# STM32L552 register map
File version: 1.5
CPU: CM33 r0p1, little endian, MPU, FPU, 3 interrupt priority bits
Registers are 32-bit, read-write, reset 0x0 unless marked. A register's access mark holds for its fields unless they carry their own. Offsets are from the block's base; [hi:lo] are bit positions; {n}, {i} and the like mark numbered series; 'fields as' and 'values as' point back to an identical list.

## TAMP — Tamper and backup registers
Base 0x40003400
Same registers: SEC_TAMP 0x50003400
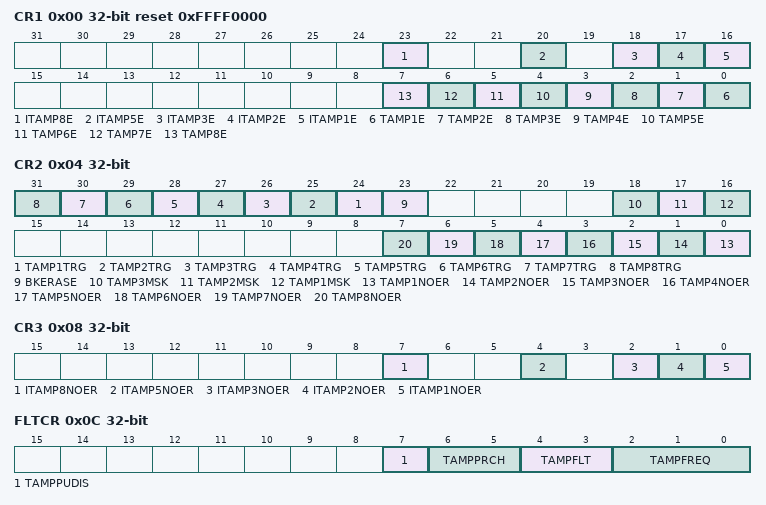
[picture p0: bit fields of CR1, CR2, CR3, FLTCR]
0x00 CR1 reset 0xFFFF0000 — control register 1
  [23] ITAMP8E — ITAMP5E
  [20] ITAMP5E
  [18] ITAMP3E
  [17] ITAMP2E
  [16] ITAMP1E
  [n-1] TAMP{n}E (n=1..8)
0x04 CR2 — control register 2
  [n+23] TAMP{n}TRG (n=1..8), [23] BKERASE, [18] TAMP3MSK, [17] TAMP2MSK, [16] TAMP1MSK, [n-1] TAMP{n}NOER (n=1..8)
0x08 CR3 — control register 3
  [7] ITAMP8NOER, [4] ITAMP5NOER, [2] ITAMP3NOER, [1] ITAMP2NOER, [0] ITAMP1NOER
0x0C FLTCR — TAMP filter control register
  [7] TAMPPUDIS, [6:5] TAMPPRCH, [4:3] TAMPFLT, [2:0] TAMPFREQ
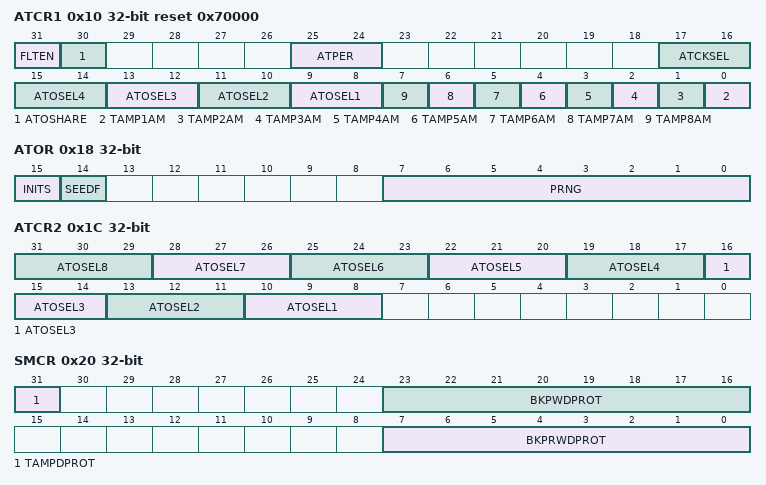
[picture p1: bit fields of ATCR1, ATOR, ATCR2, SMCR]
0x10 ATCR1 reset 0x70000 — TAMP active tamper control register 1
  [31] FLTEN, [30] ATOSHARE, [25:24] ATPER, [17:16] ATCKSEL, [2n+7:2n+6] ATOSEL{n} (n=1..4), [n-1] TAMP{n}AM (n=1..8)
0x14 ATSEEDR wo — TAMP active tamper seed register
  [31:0] SEED — Pseudo-random generator seed value
0x18 ATOR ro — TAMP active tamper output register
  [15] INITS — Active tamper initialization status
  [14] SEEDF — Seed running flag
  [7:0] PRNG — Pseudo-random generator value
0x1C ATCR2 — TAMP active tamper control register 2
  [3n+7:3n+5] ATOSEL{n} (n=1..8)
0x20 SMCR — TAMP secure mode register
  [31] TAMPDPROT — Tamper protection
  [23:16] BKPWDPROT — Backup registers write protection offset
  [7:0] BKPRWDPROT — Backup registers read/write protection offset
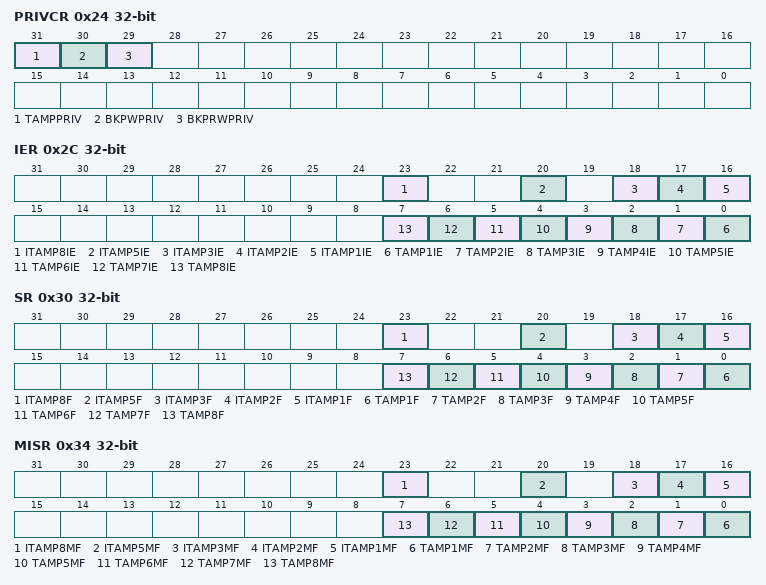
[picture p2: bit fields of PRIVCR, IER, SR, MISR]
0x24 PRIVCR — TAMP privilege mode control register
  [31] TAMPPRIV — Tamper privilege protection
  [30] BKPWPRIV — Backup registers zone 2 privilege protection
  [29] BKPRWPRIV — Backup registers zone 1 privilege protection
0x2C IER — TAMP interrupt enable register
  [23] ITAMP8IE, [20] ITAMP5IE, [18] ITAMP3IE, [17] ITAMP2IE, [16] ITAMP1IE, [n-1] TAMP{n}IE (n=1..8)
0x30 SR ro — TAMP status register
  [23] ITAMP8F, [20] ITAMP5F, [18] ITAMP3F, [17] ITAMP2F, [16] ITAMP1F, [n-1] TAMP{n}F (n=1..8)
0x34 MISR ro — TAMP masked interrupt status register
  [23] ITAMP8MF, [20] ITAMP5MF, [18] ITAMP3MF, [17] ITAMP2MF, [16] ITAMP1MF, [n-1] TAMP{n}MF (n=1..8)
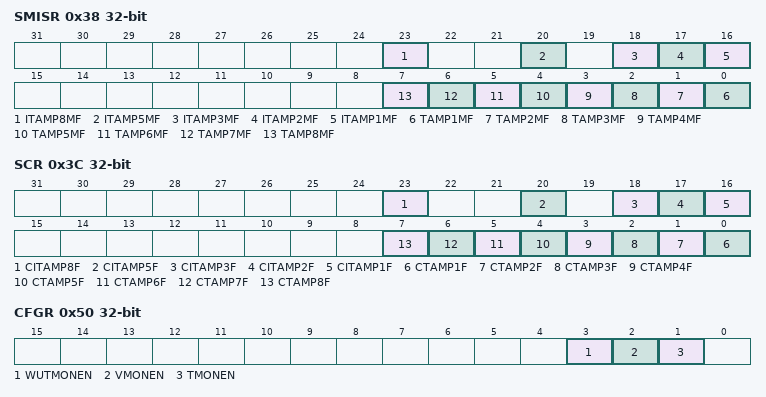
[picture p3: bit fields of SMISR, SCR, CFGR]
0x38 SMISR ro — TAMP secure masked interrupt status register
  fields as MISR
0x3C SCR wo — TAMP status clear register
  [23] CITAMP8F, [20] CITAMP5F, [18] CITAMP3F, [17] CITAMP2F, [16] CITAMP1F, [n-1] CTAMP{n}F (n=1..8)
0x40 COUNTR ro — TAMP monotonic counter register
  [31:0] COUNT
0x50 CFGR — TAMP configuration register
  [3] WUTMONEN, [2] VMONEN, [1] TMONEN
{0x100+4i} BKP{i}R (i=0..31) — TAMP backup register
  [31:0] BKP

## ICACHE
Base 0x40030400
Same registers: SEC_ICache 0x50030400
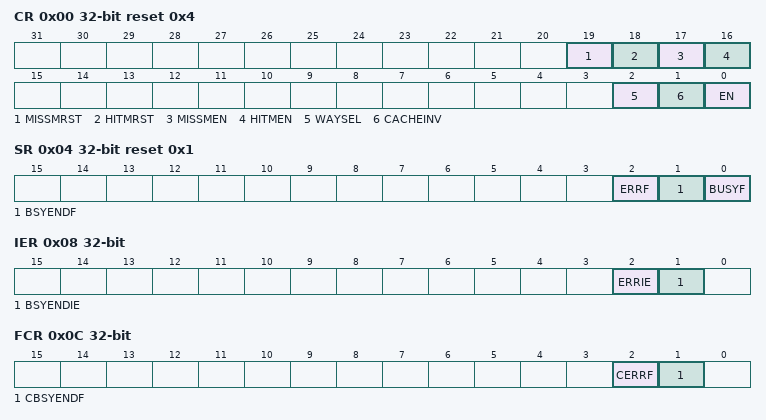
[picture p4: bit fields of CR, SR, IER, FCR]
0x00 CR reset 0x4 — ICACHE control register
  [19] MISSMRST, [18] HITMRST, [17] MISSMEN, [16] HITMEN, [2] WAYSEL, [1] CACHEINV, [0] EN
0x04 SR ro reset 0x1 — ICACHE status register
  [2] ERRF, [1] BSYENDF, [0] BUSYF
0x08 IER — ICACHE interrupt enable register
  [2] ERRIE, [1] BSYENDIE
0x0C FCR wo — ICACHE flag clear register
  [2] CERRF, [1] CBSYENDF
0x10 HMONR ro — ICACHE hit monitor register
  [31:0] HITMON
0x14 MMONR ro — ICACHE miss monitor register
  [15:0] MISSMON
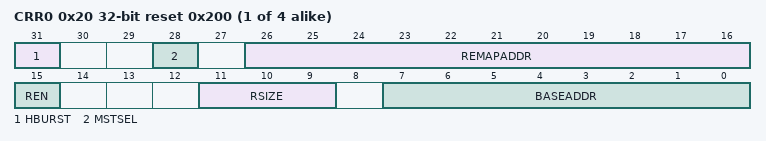
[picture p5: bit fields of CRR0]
{0x20+4i} CRR{i} (i=0..3) reset 0x200 — ICACHE region configuration register
  [31] HBURST, [28] MSTSEL, [26:16] REMAPADDR, [15] REN, [11:9] RSIZE, [7:0] BASEADDR

## IWDG — Independent watchdog
Base 0x40003000
Same registers: SEC_IWDG 0x50003000
0x00 KR wo — Key register
  [15:0] KEY — Key value (write only, read 0x0000)
0x04 PR — Prescaler register
  [2:0] PR — Prescaler divider
0x08 RLR reset 0xFFF — Reload register
  [11:0] RL — Watchdog counter reload value
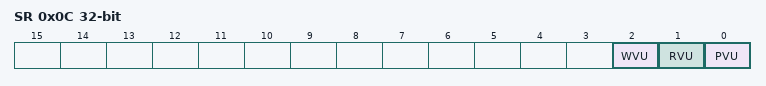
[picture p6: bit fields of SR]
0x0C SR ro — Status register
  [2] WVU — Watchdog counter window value update
  [1] RVU — Watchdog counter reload value update
  [0] PVU — Watchdog prescaler value update
0x10 WINR reset 0xFFF — Window register
  [11:0] WIN — Watchdog counter window value
